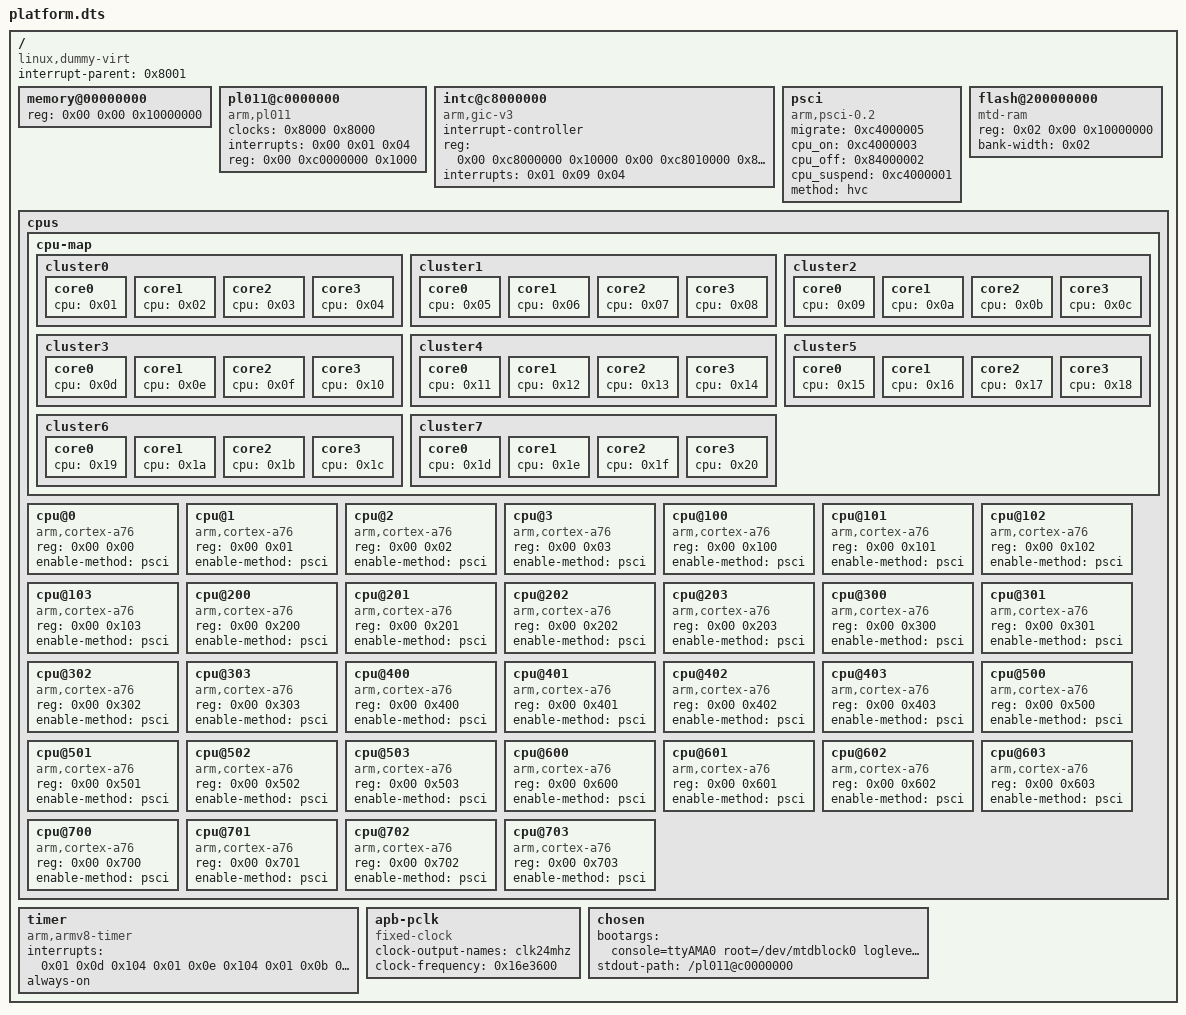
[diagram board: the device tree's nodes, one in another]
/dts-v1/;

/ {
	interrupt-parent = <0x8001>;
	#size-cells = <0x01>;
	#address-cells = <0x02>;
	compatible = "linux,dummy-virt";

	memory@00000000 {
		reg = <0x00 0x00 0x10000000>;
		device_type = "memory";
	};

	pl011@c0000000 {
		clock-names = "uartclk\0apb_pclk";
		clocks = <0x8000 0x8000>;
		interrupts = <0x00 0x01 0x04>;
		reg = <0x00 0xc0000000 0x1000>;
		compatible = "arm,pl011\0arm,primecell";
	};

	intc@c8000000 {
		compatible = "arm,gic-v3";
		#interrupt-cells = <0x03>;
		#address-cells = <0x02>;
		#size-cells = <0x02>;
		ranges;
		interrupt-controller;
		phandle = <0x8001>;
		reg = <0x00 0xc8000000 0x10000 0x00 0xc8010000 0x800000>;
		interrupts = <0x01 0x09 0x04>;
	};

	psci {
		migrate = <0xc4000005>;
		cpu_on = <0xc4000003>;
		cpu_off = <0x84000002>;
		cpu_suspend = <0xc4000001>;
		method = "hvc";
		compatible = "arm,psci-0.2\0arm,psci";
	};

    flash@200000000 {
        compatible = "mtd-ram";
        reg = <0x02 0x00 0x10000000>;
        bank-width = <0x02>;
    };

	cpus {
		#size-cells = <0x00>;
		#address-cells = <0x02>;

		cpu-map {
			cluster0 {
				core0 {
					cpu = <0x01>;
				};

				core1 {
					cpu = <0x02>;
				};

				core2 {
					cpu = <0x03>;
				};

				core3 {
					cpu = <0x04>;
				};
			};

			cluster1 {
				core0 {
					cpu = <0x05>;
				};

				core1 {
					cpu = <0x06>;
				};

				core2 {
					cpu = <0x07>;
				};

				core3 {
					cpu = <0x08>;
				};
			};

			cluster2 {
				core0 {
					cpu = <0x09>;
				};

				core1 {
					cpu = <0x0a>;
				};

				core2 {
					cpu = <0x0b>;
				};

				core3 {
					cpu = <0x0c>;
				};
			};

			cluster3 {
				core0 {
					cpu = <0x0d>;
				};

				core1 {
					cpu = <0x0e>;
				};

				core2 {
					cpu = <0x0f>;
				};

				core3 {
					cpu = <0x10>;
				};
			};

			cluster4 {
				core0 {
					cpu = <0x11>;
				};

				core1 {
					cpu = <0x12>;
				};

				core2 {
					cpu = <0x13>;
				};

				core3 {
					cpu = <0x14>;
				};
			};

			cluster5 {
				core0 {
					cpu = <0x15>;
				};

				core1 {
					cpu = <0x16>;
				};

				core2 {
					cpu = <0x17>;
				};

				core3 {
					cpu = <0x18>;
				};
			};

			cluster6 {
				core0 {
					cpu = <0x19>;
				};

				core1 {
					cpu = <0x1a>;
				};

				core2 {
					cpu = <0x1b>;
				};

				core3 {
					cpu = <0x1c>;
				};
			};

			cluster7 {
				core0 {
					cpu = <0x1d>;
				};

				core1 {
					cpu = <0x1e>;
				};

				core2 {
					cpu = <0x1f>;
				};

				core3 {
					cpu = <0x20>;
				};
			};
        };

		cpu@0 {
			device_type = "cpu";
			compatible = "arm,cortex-a76";
			reg = <0x00 0x00>;
			enable-method = "psci";
			phandle = <0x01>;
		};

		cpu@1 {
			device_type = "cpu";
			compatible = "arm,cortex-a76";
			reg = <0x00 0x01>;
			enable-method = "psci";
			phandle = <0x02>;
		};

		cpu@2 {
			device_type = "cpu";
			compatible = "arm,cortex-a76";
			reg = <0x00 0x02>;
			enable-method = "psci";
			phandle = <0x03>;
		};

		cpu@3 {
			device_type = "cpu";
			compatible = "arm,cortex-a76";
			reg = <0x00 0x03>;
			enable-method = "psci";
			phandle = <0x04>;
		};

		cpu@100 {
			device_type = "cpu";
			compatible = "arm,cortex-a76";
			reg = <0x00 0x100>;
			enable-method = "psci";
			phandle = <0x05>;
		};

		cpu@101 {
			device_type = "cpu";
			compatible = "arm,cortex-a76";
			reg = <0x00 0x101>;
			enable-method = "psci";
			phandle = <0x06>;
		};

		cpu@102 {
			device_type = "cpu";
			compatible = "arm,cortex-a76";
			reg = <0x00 0x102>;
			enable-method = "psci";
			phandle = <0x07>;
		};

		cpu@103 {
			device_type = "cpu";
			compatible = "arm,cortex-a76";
			reg = <0x00 0x103>;
			enable-method = "psci";
			phandle = <0x08>;
		};

		cpu@200 {
			device_type = "cpu";
			compatible = "arm,cortex-a76";
			reg = <0x00 0x200>;
			enable-method = "psci";
			phandle = <0x09>;
		};

		cpu@201 {
			device_type = "cpu";
			compatible = "arm,cortex-a76";
			reg = <0x00 0x201>;
			enable-method = "psci";
			phandle = <0x0a>;
		};

		cpu@202 {
			device_type = "cpu";
			compatible = "arm,cortex-a76";
			reg = <0x00 0x202>;
			enable-method = "psci";
			phandle = <0x0b>;
		};

		cpu@203 {
			device_type = "cpu";
			compatible = "arm,cortex-a76";
			reg = <0x00 0x203>;
			enable-method = "psci";
			phandle = <0x0c>;
		};

		cpu@300 {
			device_type = "cpu";
			compatible = "arm,cortex-a76";
			reg = <0x00 0x300>;
			enable-method = "psci";
			phandle = <0x0d>;
		};

		cpu@301 {
			device_type = "cpu";
			compatible = "arm,cortex-a76";
			reg = <0x00 0x301>;
			enable-method = "psci";
			phandle = <0x0e>;
		};

		cpu@302 {
			device_type = "cpu";
			compatible = "arm,cortex-a76";
			reg = <0x00 0x302>;
			enable-method = "psci";
			phandle = <0x0f>;
		};

		cpu@303 {
			device_type = "cpu";
			compatible = "arm,cortex-a76";
			reg = <0x00 0x303>;
			enable-method = "psci";
			phandle = <0x10>;
		};

		cpu@400 {
			device_type = "cpu";
			compatible = "arm,cortex-a76";
			reg = <0x00 0x400>;
			enable-method = "psci";
			phandle = <0x11>;
		};

		cpu@401 {
			device_type = "cpu";
			compatible = "arm,cortex-a76";
			reg = <0x00 0x401>;
			enable-method = "psci";
			phandle = <0x12>;
		};

		cpu@402 {
			device_type = "cpu";
			compatible = "arm,cortex-a76";
			reg = <0x00 0x402>;
			enable-method = "psci";
			phandle = <0x13>;
		};

		cpu@403 {
			device_type = "cpu";
			compatible = "arm,cortex-a76";
			reg = <0x00 0x403>;
			enable-method = "psci";
			phandle = <0x14>;
		};

		cpu@500 {
			device_type = "cpu";
			compatible = "arm,cortex-a76";
			reg = <0x00 0x500>;
			enable-method = "psci";
			phandle = <0x15>;
		};

		cpu@501 {
			device_type = "cpu";
			compatible = "arm,cortex-a76";
			reg = <0x00 0x501>;
			enable-method = "psci";
			phandle = <0x16>;
		};

		cpu@502 {
			device_type = "cpu";
			compatible = "arm,cortex-a76";
			reg = <0x00 0x502>;
			enable-method = "psci";
			phandle = <0x17>;
		};

		cpu@503 {
			device_type = "cpu";
			compatible = "arm,cortex-a76";
			reg = <0x00 0x503>;
			enable-method = "psci";
			phandle = <0x18>;
		};

		cpu@600 {
			device_type = "cpu";
			compatible = "arm,cortex-a76";
			reg = <0x00 0x600>;
			enable-method = "psci";
			phandle = <0x19>;
		};

		cpu@601 {
			device_type = "cpu";
			compatible = "arm,cortex-a76";
			reg = <0x00 0x601>;
			enable-method = "psci";
			phandle = <0x1a>;
		};

		cpu@602 {
			device_type = "cpu";
			compatible = "arm,cortex-a76";
			reg = <0x00 0x602>;
			enable-method = "psci";
			phandle = <0x1b>;
		};

		cpu@603 {
			device_type = "cpu";
			compatible = "arm,cortex-a76";
			reg = <0x00 0x603>;
			enable-method = "psci";
			phandle = <0x1c>;
		};

		cpu@700 {
			device_type = "cpu";
			compatible = "arm,cortex-a76";
			reg = <0x00 0x700>;
			enable-method = "psci";
			phandle = <0x1d>;
		};

		cpu@701 {
			device_type = "cpu";
			compatible = "arm,cortex-a76";
			reg = <0x00 0x701>;
			enable-method = "psci";
			phandle = <0x1e>;
		};

		cpu@702 {
			device_type = "cpu";
			compatible = "arm,cortex-a76";
			reg = <0x00 0x702>;
			enable-method = "psci";
			phandle = <0x1f>;
		};

		cpu@703 {
			device_type = "cpu";
			compatible = "arm,cortex-a76";
			reg = <0x00 0x703>;
			enable-method = "psci";
			phandle = <0x20>;
		};
	};

	timer {
		interrupts = <0x01 0x0d 0x104 0x01 0x0e 0x104 0x01 0x0b 0x104 0x01 0x0a 0x104>;
		always-on;
		compatible = "arm,armv8-timer\0arm,armv7-timer";
	};

	apb-pclk {
		phandle = <0x8000>;
		clock-output-names = "clk24mhz";
		clock-frequency = <0x16e3600>;
		#clock-cells = <0x00>;
		compatible = "fixed-clock";
	};

	chosen {
		bootargs = "console=ttyAMA0 root=/dev/mtdblock0 loglevel=8 earlyprintk earlycon";
		stdout-path = "/pl011@c0000000";
	};
};
